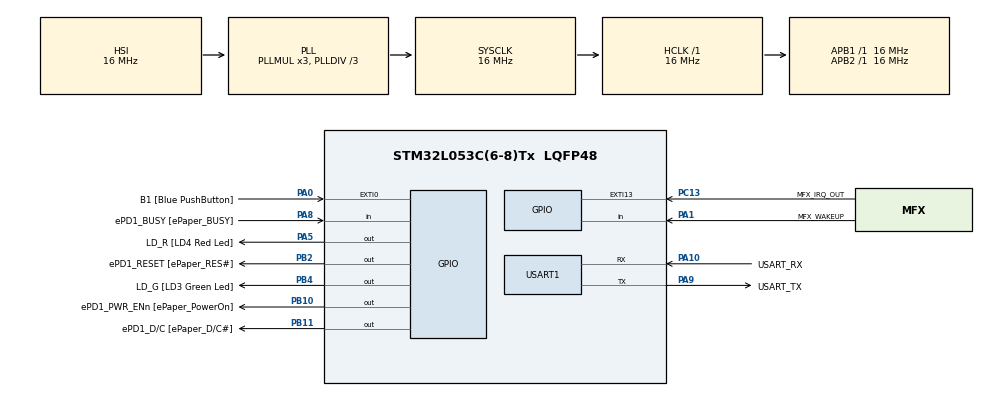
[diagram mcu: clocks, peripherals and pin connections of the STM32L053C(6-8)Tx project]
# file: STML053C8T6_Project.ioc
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IWDG.Prescaler=IWDG_PRESCALER_32
IWDG.Reload=2312
Mcu.Family=STM32L0
Mcu.Name=STM32L053C(6-8)Tx
Mcu.Package=LQFP48
NVIC.USART1_IRQn=true\:0\:0\:false\:false\:true\:true\:true\:true
PA0.GPIO_Label=B1 [Blue PushButton]
PA0.GPIO_ModeDefaultEXTI=GPIO_MODE_EVT_RISING
PA0.GPIO_PuPd=GPIO_NOPULL
PA0.Signal=GPXTI0
PA1.GPIO_Label=MFX_WAKEUP
PA1.Signal=GPIO_Input
PA10.GPIO_Label=USART_RX
PA10.Mode=Asynchronous
PA10.Signal=USART1_RX
PA11.GPIO_Label=USB1_DM
PA11.Signal=USB_DM
PA12.GPIO_Label=USB1_DP
PA12.Signal=USB_DP
PA13.GPIO_Label=SWDIO
PA13.Signal=SYS_SWDIO
PA15.GPIO_Label=ePD1_CS [ePaper_CS\#]
PA15.GPIO_Mode=GPIO_MODE_AF_PP
PA15.GPIO_PuPd=GPIO_NOPULL
PA15.GPIO_Speed=GPIO_SPEED_FREQ_LOW
PA15.Signal=SPI1_NSS
PA2.Signal=TSC_G1_IO3
PA3.Signal=TSC_G1_IO4
PA5.GPIO_Label=LD_R [LD4 Red Led]
PA5.GPIO_ModeDefaultOutputPP=GPIO_MODE_OUTPUT_PP
PA5.GPIO_PuPd=GPIO_NOPULL
PA5.GPIO_Speed=GPIO_SPEED_FREQ_LOW
PA5.Signal=GPIO_Output
PA6.Signal=TSC_G2_IO3
PA7.Signal=TSC_G2_IO4
PA8.GPIO_Label=ePD1_BUSY [ePaper_BUSY]
PA8.GPIO_Mode=GPIO_MODE_INPUT
PA8.GPIO_PuPd=GPIO_NOPULL
PA8.Signal=GPIO_Input
PA9.GPIO_Label=USART_TX
PA9.Mode=Asynchronous
PA9.Signal=USART1_TX
PB0.Signal=TSC_G3_IO2
PB1.Signal=TSC_G3_IO3
PB10.GPIO_Label=ePD1_PWR_ENn [ePaper_PowerOn]
PB10.GPIO_ModeDefaultOutputPP=GPIO_MODE_OUTPUT_PP
PB10.GPIO_PuPd=GPIO_NOPULL
PB10.GPIO_Speed=GPIO_SPEED_FREQ_LOW
PB10.Signal=GPIO_Output
PB11.GPIO_Label=ePD1_D/C [ePaper_D/C\#]
PB11.GPIO_ModeDefaultOutputPP=GPIO_MODE_OUTPUT_PP
PB11.GPIO_PuPd=GPIO_NOPULL
PB11.GPIO_Speed=GPIO_SPEED_FREQ_LOW
PB11.Signal=GPIO_Output
PB12.GPIO_Label=NFC_NSS
PB12.Signal=SPI2_NSS
PB13.GPIO_Label=NFC_SCK
PB13.Signal=SPI2_SCK
PB14.GPIO_Label=NFC_MISO
PB14.Signal=SPI2_MISO
PB15.GPIO_Label=NFC_MOSI
PB15.Signal=SPI2_MOSI
PB2.GPIO_Label=ePD1_RESET [ePaper_RES\#]
PB2.GPIO_ModeDefaultOutputPP=GPIO_MODE_OUTPUT_PP
PB2.GPIO_PuPd=GPIO_NOPULL
PB2.GPIO_Speed=GPIO_SPEED_FREQ_LOW
PB2.Signal=GPIO_Output
PB3.GPIO_Label=ePD1_SCK [ePaper_SCK]
PB3.GPIO_Mode=GPIO_MODE_AF_PP
PB3.GPIO_PuPd=GPIO_NOPULL
PB3.GPIO_Speed=GPIO_SPEED_FREQ_LOW
PB3.Signal=SPI1_SCK
PB4.GPIO_Label=LD_G [LD3 Green Led]
PB4.GPIO_ModeDefaultOutputPP=GPIO_MODE_OUTPUT_PP
PB4.GPIO_PuPd=GPIO_NOPULL
PB4.GPIO_Speed=GPIO_SPEED_FREQ_LOW
PB4.Signal=GPIO_Output
PB5.GPIO_Label=ePD1_MOSI [ePaper_MOSI]
PB5.GPIO_Mode=GPIO_MODE_AF_PP
PB5.GPIO_PuPd=GPIO_NOPULL
PB5.GPIO_Speed=GPIO_SPEED_FREQ_LOW
PB5.Signal=SPI1_MOSI
PB8.GPIO_Label=MFX_I2C_SCL
PB8.Signal=I2C1_SCL
PB9.GPIO_Label=MFX_I2C_SDA
PB9.Signal=I2C1_SDA
PC13.GPIO_Label=MFX_IRQ_OUT
PC13.Signal=GPXTI13
PC14-OSC32_IN.GPIO_Label=PC14-OSC32_IN
PC14-OSC32_IN.Signal=RCC_OSC32_IN
PC15-OSC32_OUT.GPIO_Label=PC15-OSC32_OUT
PC15-OSC32_OUT.Signal=RCC_OSC32_OUT
PH0-OSC_IN.GPIO_Label=MCO
PH0-OSC_IN.Signal=RCC_OSC_IN
ProjectManager.HeapSize=0x200
ProjectManager.StackSize=0x400
ProjectManager.TargetToolchain=MDK-ARM V5.32
RCC.AHBFreq_Value=16000000
RCC.APB1Freq_Value=16000000
RCC.APB1TimFreq_Value=16000000
RCC.APB2Freq_Value=16000000
RCC.APB2TimFreq_Value=16000000
RCC.HCLKFreq_Value=16000000
RCC.HSE_VALUE=8000000
RCC.HSI16_VALUE=16000000
RCC.HSI48MClockSelection=RCC_USBCLKSOURCE_HSI48
RCC.HSI48_VALUE=48000000
RCC.HSI_VALUE=16000000
RCC.LSE_VALUE=32768
RCC.MSI_VALUE=2097000
RCC.PLLDIV=RCC_PLLDIV_3
RCC.RTCClockSelectionVirtual=RCC_RTCCLKSOURCE_LSE
RCC.SYSCLKFreq_VALUE=16000000
RCC.SYSCLKSource=RCC_SYSCLKSOURCE_PLLCLK
RCC.VCOOutputFreq_Value=48000000
USART1.Parity=PARITY_ODD
USART1.VirtualMode-Asynchronous=VM_ASYNC
USART1.WordLength=WORDLENGTH_9B
VP_IWDG_VS_IWDG.Mode=IWDG_Activate
board=STM32L0538-DISCO

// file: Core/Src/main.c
/* USER CODE BEGIN Header */
/**
  ******************************************************************************
  * @file           : main.c
  * @brief          : Main program body
  ******************************************************************************
  * @attention
  *
  * Copyright (c) 2022 STMicroelectronics.
  * All rights reserved.
  *
  * This software is licensed under terms that can be found in the LICENSE file
  * in the root directory of this software component.
  * If no LICENSE file comes with this software, it is provided AS-IS.
  *
  ******************************************************************************
  */
/* USER CODE END Header */
#include "main.h"
#include "iwdg.h"
#include "usart.h"
#include "gpio.h"

void SystemClock_Config(void);

int main(void)
{

  /* MCU Configuration--------------------------------------------------------*/

  /* Reset of all peripherals, Initializes the Flash interface and the Systick. */
  HAL_Init();

  /* Configure the system clock */
  SystemClock_Config();

  /* Initialize all configured peripherals */
  MX_GPIO_Init();
  MX_USART1_UART_Init();
  MX_IWDG_Init();
  /* USER CODE BEGIN 2 */

	comInit();

  /* USER CODE END 2 */

  /* Infinite loop */
  while (1)
  {

    /* USER CODE BEGIN 3 */

		comHandler();

		HAL_IWDG_Refresh(&hiwdg);
  }

  /* USER CODE END 3 */
}

void SystemClock_Config(void)
{
  RCC_OscInitTypeDef RCC_OscInitStruct = {0};
  RCC_ClkInitTypeDef RCC_ClkInitStruct = {0};
  RCC_PeriphCLKInitTypeDef PeriphClkInit = {0};

  /** Configure the main internal regulator output voltage
  */
  __HAL_PWR_VOLTAGESCALING_CONFIG(PWR_REGULATOR_VOLTAGE_SCALE1);

  /** Initializes the RCC Oscillators according to the specified parameters
  * in the RCC_OscInitTypeDef structure.
  */
  RCC_OscInitStruct.OscillatorType = RCC_OSCILLATORTYPE_HSI|RCC_OSCILLATORTYPE_LSI;
  RCC_OscInitStruct.HSIState = RCC_HSI_ON;
  RCC_OscInitStruct.HSICalibrationValue = RCC_HSICALIBRATION_DEFAULT;
  RCC_OscInitStruct.LSIState = RCC_LSI_ON;
  RCC_OscInitStruct.PLL.PLLState = RCC_PLL_ON;
  RCC_OscInitStruct.PLL.PLLSource = RCC_PLLSOURCE_HSI;
  RCC_OscInitStruct.PLL.PLLMUL = RCC_PLLMUL_3;
  RCC_OscInitStruct.PLL.PLLDIV = RCC_PLLDIV_3;
  if (HAL_RCC_OscConfig(&RCC_OscInitStruct) != HAL_OK)
  {
    Error_Handler();
  }

  /** Initializes the CPU, AHB and APB buses clocks
  */
  RCC_ClkInitStruct.ClockType = RCC_CLOCKTYPE_HCLK|RCC_CLOCKTYPE_SYSCLK
                              |RCC_CLOCKTYPE_PCLK1|RCC_CLOCKTYPE_PCLK2;
  RCC_ClkInitStruct.SYSCLKSource = RCC_SYSCLKSOURCE_PLLCLK;
  RCC_ClkInitStruct.AHBCLKDivider = RCC_SYSCLK_DIV1;
  RCC_ClkInitStruct.APB1CLKDivider = RCC_HCLK_DIV1;
  RCC_ClkInitStruct.APB2CLKDivider = RCC_HCLK_DIV1;

  if (HAL_RCC_ClockConfig(&RCC_ClkInitStruct, FLASH_LATENCY_0) != HAL_OK)
  {
    Error_Handler();
  }
  PeriphClkInit.PeriphClockSelection = RCC_PERIPHCLK_USART1;
  PeriphClkInit.Usart1ClockSelection = RCC_USART1CLKSOURCE_PCLK2;
  if (HAL_RCCEx_PeriphCLKConfig(&PeriphClkInit) != HAL_OK)
  {
    Error_Handler();
  }
}

/* USER CODE BEGIN 4 */

	//Rx Cpmltd Callback
		void HAL_UART_RxCpltCallback(UART_HandleTypeDef *huart){

			rxBufIndisCntr++;
			rxByteTimeout = 1;	//Set rx byte timeout
			comStatus = COM_RX_START;
		}

	//Tx Cpmltd Callback
		void HAL_UART_TxCpltCallback(UART_HandleTypeDef *huart){

			txNewMsgTimeout = 1; //Set tx new msg timeout
			comStatus = COM_TX_CMPLTD;
		}

/* USER CODE END 4 */

void Error_Handler(void)
{
  __disable_irq();
  while (1)
  {
  }
}
